VERSION "tio-gui example"
NS_ :

BS_:
BU_: Board Host
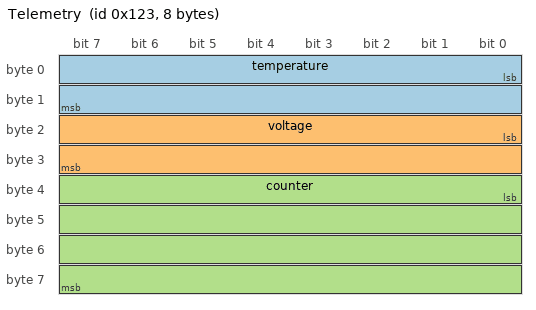
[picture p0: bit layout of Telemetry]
BO_ 291 Telemetry: 8 Board
 SG_ temperature : 0|16@1- (0.1,0) [-3276.8|3276.7] "C" Host
 SG_ voltage : 16|16@1+ (0.001,0) [0|65.535] "V" Host
 SG_ counter : 32|32@1+ (1,0) [0|4294967295] "" Host
